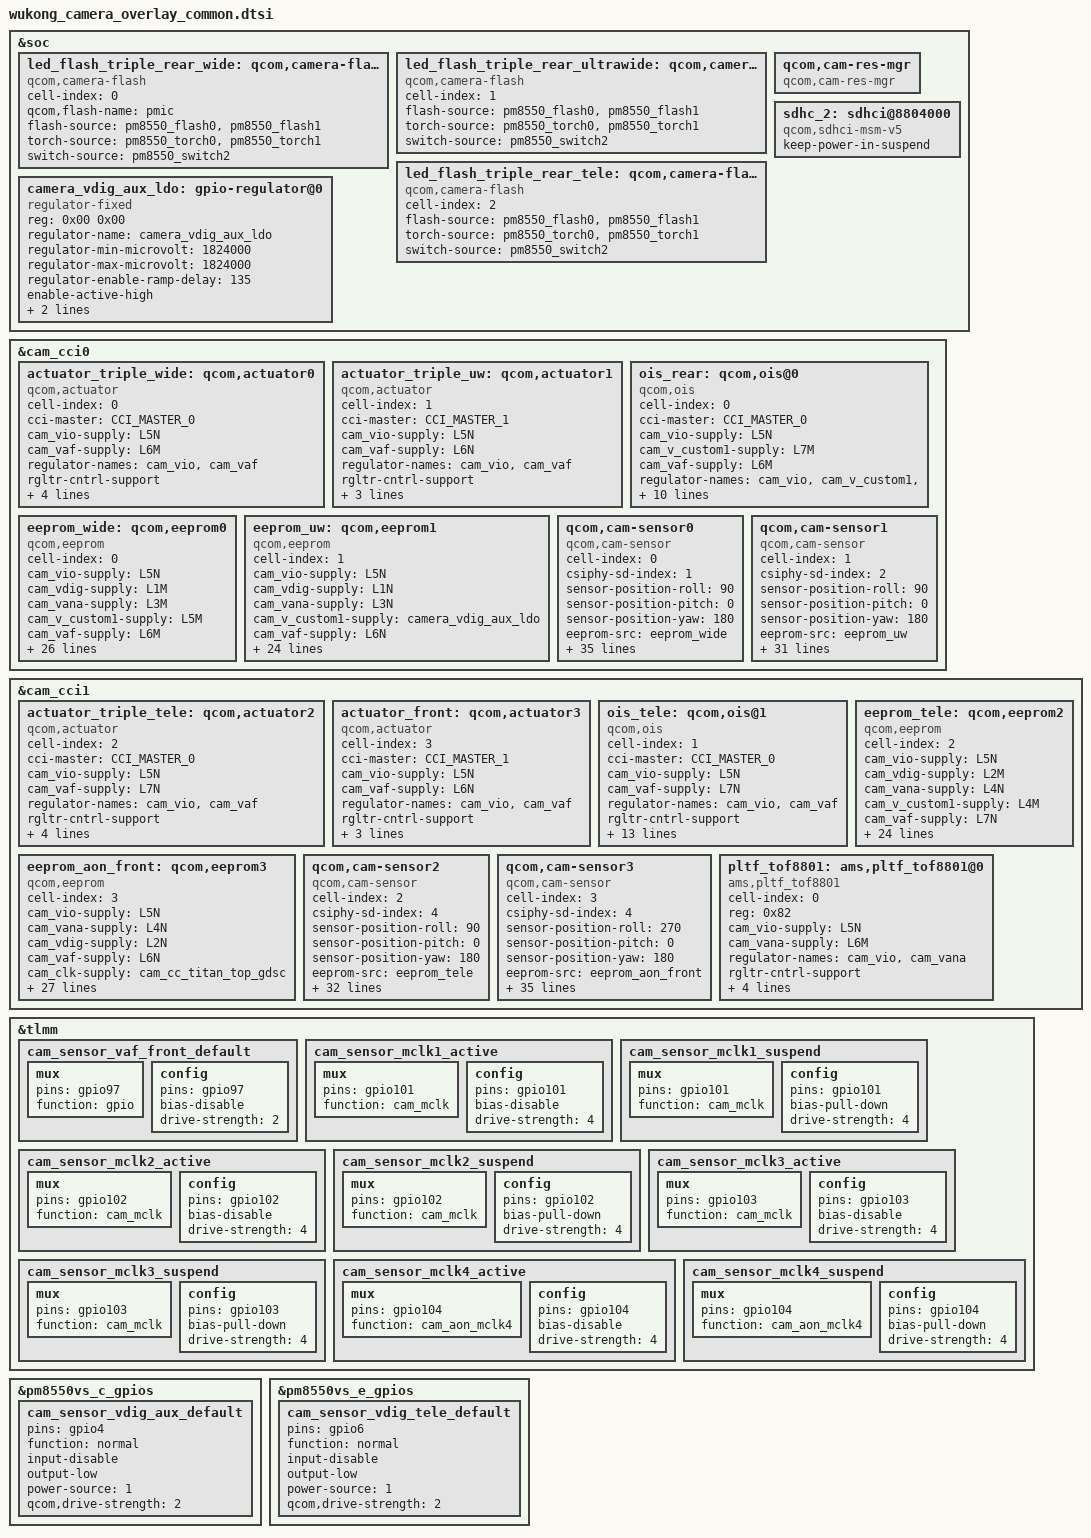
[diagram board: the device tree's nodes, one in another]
#include <dt-bindings/msm-camera.h>

&soc {
	led_flash_triple_rear_wide: qcom,camera-flash0 {
		cell-index = <0>;
		compatible = "qcom,camera-flash";
		qcom,flash-name = "pmic";
		flash-source = <&pm8550_flash0 &pm8550_flash1>;
		torch-source = <&pm8550_torch0 &pm8550_torch1>;
		switch-source = <&pm8550_switch2>;
		status = "ok";
	};

	led_flash_triple_rear_ultrawide: qcom,camera-flash1 {
		cell-index = <1>;
		compatible = "qcom,camera-flash";
		flash-source = <&pm8550_flash0 &pm8550_flash1>;
		torch-source = <&pm8550_torch0 &pm8550_torch1>;
		switch-source = <&pm8550_switch2>;
		status = "ok";
	};

	led_flash_triple_rear_tele: qcom,camera-flash2 {
		cell-index = <2>;
		compatible = "qcom,camera-flash";
		flash-source = <&pm8550_flash0 &pm8550_flash1>;
		torch-source = <&pm8550_torch0 &pm8550_torch1>;
		switch-source = <&pm8550_switch2>;
		status = "ok";
	};

	camera_vdig_aux_ldo: gpio-regulator@0 {
		compatible = "regulator-fixed";
		reg = <0x00 0x00>;
		regulator-name = "camera_vdig_aux_ldo";
		regulator-min-microvolt = <1824000>;
		regulator-max-microvolt = <1824000>;
		regulator-enable-ramp-delay = <135>;
		enable-active-high;
		gpio = <&pm8550vs_c_gpios 4 0>;
		pinctrl-names = "default";
		pinctrl-0 = <&cam_sensor_vdig_aux_default>;
		//vin-supply = <&S6G>;
	};


	qcom,cam-res-mgr {
		compatible = "qcom,cam-res-mgr";
		status = "ok";
	};

	sdhc_2: sdhci@8804000 {
		compatible = "qcom,sdhci-msm-v5";
		keep-power-in-suspend;
		status = "ok";
	};
};



&cam_cci0 {
	actuator_triple_wide: qcom,actuator0 {
		cell-index = <0>;
		compatible = "qcom,actuator";
		cci-master = <CCI_MASTER_0>;
		cam_vio-supply = <&L5N>;
		cam_vaf-supply = <&L6M>;
		regulator-names = "cam_vio", "cam_vaf";
		rgltr-cntrl-support;
		rgltr-min-voltage = <1800000 3152000>;
		rgltr-max-voltage = <1800000 3152000>;
		rgltr-load-current = <600000 300000>;
		is_af_parklens = <1>;
		status = "ok";
	};

	actuator_triple_uw: qcom,actuator1 {
		cell-index = <1>;
		compatible = "qcom,actuator";
		cci-master = <CCI_MASTER_1>;
		cam_vio-supply = <&L5N>;
		cam_vaf-supply = <&L6N>;
		regulator-names = "cam_vio", "cam_vaf";
		rgltr-cntrl-support;
		rgltr-min-voltage = <1800000 2800000>;
		rgltr-max-voltage = <1800000 2800000>;
		rgltr-load-current = <600000 300000>;
		status = "ok";
	};

	ois_rear: qcom,ois@0{
		cell-index = <0>;
		compatible = "qcom,ois";
		cci-master = <CCI_MASTER_0>;
		cam_vio-supply = <&L5N>;
		cam_v_custom1-supply = <&L7M>;
		cam_vaf-supply = <&L6M>;
		regulator-names = "cam_vio","cam_v_custom1", "cam_vaf";
		rgltr-cntrl-support;
		rgltr-min-voltage = <1800000 3152000 3152000>;
		rgltr-max-voltage = <1800000 3152000 3152000>;
		rgltr-load-current = <600000 300000 300000>;
		ois_gyro,position=<3>;
		ois_gyro,type=<3>;
		ois,type=<0>;
		ois,name="ak7323";
		ois,fw=<1>;
		status = "ok";
	};

	eeprom_wide: qcom,eeprom0 {
		cell-index = <0>;
		compatible = "qcom,eeprom";
		cam_vio-supply = <&L5N>;
		cam_vdig-supply = <&L1M>;
		cam_vana-supply = <&L3M>;
		cam_v_custom1-supply = <&L5M>;
		cam_vaf-supply = <&L6M>;
		cam_v_custom2-supply = <&L7M>;
		cam_clk-supply = <&cam_cc_titan_top_gdsc>;
		regulator-names = "cam_vio", "cam_vana", "cam_v_custom1", "cam_vdig", "cam_vaf","cam_v_custom2",
		                  "cam_clk";
		rgltr-cntrl-support;
		rgltr-min-voltage = <1800000 2904000 1800000 1152000 3152000 3152000 0>;
		rgltr-max-voltage = <1800000 2904000 1800000 1152000 3152000 3152000 0>;
		rgltr-load-current = <600000 600000 300000 1200000 300000 300000 0>;
		gpio-no-mux = <0>;
		pinctrl-names = "cam_default", "cam_suspend";
		pinctrl-0 = <&cam_sensor_mclk2_active
			&cam_sensor_active_rst1>;
		pinctrl-1 = <&cam_sensor_mclk2_suspend
			&cam_sensor_suspend_rst1>;
		gpios = <&tlmm 102 0>,
			<&tlmm 117 0>;
		gpio-reset = <1>;
		gpio-req-tbl-num = <0 1>;
		gpio-req-tbl-flags = <1 0>;
		gpio-req-tbl-label = "CAMIF_MCLK2",
					"CAM_RESET1";
		cci-master = <CCI_MASTER_0>;
		clocks = <&camcc CAM_CC_MCLK2_CLK>;
		clock-names = "cam_clk";
		clock-cntl-level = "nominal";
		clock-rates = <19200000>;
		status = "ok";
	};

	eeprom_uw: qcom,eeprom1 {
		cell-index = <1>;
		compatible = "qcom,eeprom";
		cam_vio-supply = <&L5N>;
		cam_vdig-supply = <&L1N>;
		cam_vana-supply = <&L3N>;
		cam_v_custom1-supply = <&camera_vdig_aux_ldo>;
		cam_vaf-supply = <&L6N>;
		cam_clk-supply = <&cam_cc_titan_top_gdsc>;
		regulator-names = "cam_vio", "cam_vana", "cam_v_custom1", "cam_vaf",
			"cam_vdig", "cam_clk";
		rgltr-cntrl-support;
		rgltr-min-voltage = <1800000 2800000 1824000 2800000 1152000 0>;
		rgltr-max-voltage = <1800000 2800000 1824000 2800000 1152000 0>;
		rgltr-load-current = <600000 300000 400000 300000 1200000 0>;
		gpio-no-mux = <0>;
		pinctrl-names = "cam_default", "cam_suspend";
		pinctrl-0 = <&cam_sensor_mclk1_active
				 &cam_sensor_active_rst2>;
		pinctrl-1 = <&cam_sensor_mclk1_suspend
				 &cam_sensor_suspend_rst2>;
		gpios = <&tlmm 101 0>,
			<&tlmm 118 0>;
		gpio-reset = <1>;
		gpio-req-tbl-num = <0 1>;
		gpio-req-tbl-flags = <1 0>;
		gpio-req-tbl-label = "CAMIF_MCLK1",
					"CAM_RESET2";
		cci-master = <CCI_MASTER_1>;
		clocks = <&camcc CAM_CC_MCLK1_CLK>;
		clock-names = "cam_clk";
		clock-cntl-level = "nominal";
		clock-rates = <19200000>;
		status = "ok";
	};
    //main camera
	qcom,cam-sensor0 {
		cell-index = <0>;
		compatible = "qcom,cam-sensor";
		csiphy-sd-index = <1>;
		sensor-position-roll = <90>;
		sensor-position-pitch = <0>;
		sensor-position-yaw = <180>;
		eeprom-src = <&eeprom_wide>;
		actuator-src = <&actuator_triple_wide>;
		led-flash-src = <&led_flash_triple_rear_wide>;
		ois-src = <&ois_rear>;
		cam_vio-supply = <&L5N>;
		cam_vdig-supply = <&L1M>;
		cam_vana-supply = <&L3M>;
		cam_v_custom1-supply = <&L5M>;
		cam_vaf-supply = <&L6M>;
		cam_v_custom2-supply = <&L7M>;
		cam_clk-supply = <&cam_cc_titan_top_gdsc>;
		regulator-names = "cam_vio", "cam_vana", "cam_v_custom1", "cam_vdig", "cam_vaf","cam_v_custom2",
		                  "cam_clk";
		rgltr-cntrl-support;
		rgltr-min-voltage = <1800000 2904000 1800000 1152000 3152000 3152000 0>;
		rgltr-max-voltage = <1800000 2904000 1800000 1152000 3152000 3152000 0>;
		rgltr-load-current = <600000 600000 300000 1200000 300000 300000 0>;
		gpio-no-mux = <0>;
		pinctrl-names = "cam_default", "cam_suspend";
		pinctrl-0 = <&cam_sensor_mclk2_active
			&cam_sensor_active_rst1>;
		pinctrl-1 = <&cam_sensor_mclk2_suspend
			&cam_sensor_suspend_rst1>;
		gpios = <&tlmm 102 0>,
			<&tlmm 117 0>;
		gpio-reset = <1>;
		gpio-req-tbl-num = <0 1>;
		gpio-req-tbl-flags = <1 0>;
		gpio-req-tbl-label = "CAMIF_MCLK2",
					"CAM_RESET1";
		cci-master = <CCI_MASTER_0>;
		clocks = <&camcc CAM_CC_MCLK2_CLK>;
		clock-names = "cam_clk";
		clock-cntl-level = "nominal";
		clock-rates = <19200000>;
		is-support-laser = <1>;
		status = "ok";
	};
    //wide camera
	qcom,cam-sensor1 {
		cell-index = <1>;
		compatible = "qcom,cam-sensor";
		csiphy-sd-index = <2>;
		sensor-position-roll = <90>;
		sensor-position-pitch = <0>;
		sensor-position-yaw = <180>;
		eeprom-src = <&eeprom_uw>;
		actuator-src = <&actuator_triple_uw>;
		led-flash-src = <&led_flash_triple_rear_ultrawide>;
		cam_vio-supply = <&L5N>;
		cam_vdig-supply = <&L1N>;
		cam_vana-supply = <&L3N>;
		cam_v_custom1-supply = <&camera_vdig_aux_ldo>;
		cam_vaf-supply = <&L6N>;
		cam_clk-supply = <&cam_cc_titan_top_gdsc>;
		regulator-names = "cam_vio", "cam_vana", "cam_v_custom1", "cam_vaf",
			"cam_vdig", "cam_clk";
		rgltr-cntrl-support;
		rgltr-min-voltage = <1800000 2800000 1824000 2800000 1152000 0>;
		rgltr-max-voltage = <1800000 2800000 1824000 2800000 1152000 0>;
		rgltr-load-current = <600000 300000 400000 300000 1200000 0>;
		gpio-no-mux = <0>;
		pinctrl-names = "cam_default", "cam_suspend";
		pinctrl-0 = <&cam_sensor_mclk1_active
				 &cam_sensor_active_rst2>;
		pinctrl-1 = <&cam_sensor_mclk1_suspend
				 &cam_sensor_suspend_rst2>;
		gpios = <&tlmm 101 0>,
			<&tlmm 118 0>;
		gpio-reset = <1>;
		gpio-req-tbl-num = <0 1>;
		gpio-req-tbl-flags = <1 0>;
		gpio-req-tbl-label = "CAMIF_MCLK1",
					"CAM_RESET2";
		cci-master = <CCI_MASTER_1>;
		clocks = <&camcc CAM_CC_MCLK1_CLK>;
		clock-names = "cam_clk";
		clock-cntl-level = "nominal";
		clock-rates = <19200000>;
		status = "ok";
	};

};

&cam_cci1 {
	actuator_triple_tele: qcom,actuator2{
		cell-index = <2>;
		compatible = "qcom,actuator";
		cci-master = <CCI_MASTER_0>;
		cam_vio-supply = <&L5N>;
		cam_vaf-supply = <&L7N>;
		regulator-names = "cam_vio","cam_vaf";
		rgltr-cntrl-support;
		rgltr-min-voltage = <1800000 2800000>;
		rgltr-max-voltage = <1800000 2800000>;
		rgltr-load-current = <600000 600000>;
		is_update_pid;
		status = "ok";
	};

	actuator_front: qcom,actuator3{
		cell-index = <3>;
		compatible = "qcom,actuator";
		cci-master = <CCI_MASTER_1>;
		cam_vio-supply = <&L5N>;
		cam_vaf-supply = <&L6N>;
		regulator-names = "cam_vio", "cam_vaf";
		rgltr-cntrl-support;
		rgltr-min-voltage = <1800000 2800000>;
		rgltr-max-voltage = <1800000 2800000>;
		rgltr-load-current = <600000 300000>;
		status = "ok";
	};

	ois_tele: qcom,ois@1{
		cell-index = <1>;
		compatible = "qcom,ois";
		cci-master = <CCI_MASTER_0>;
		cam_vio-supply = <&L5N>;
		cam_vaf-supply = <&L7N>;
		regulator-names = "cam_vio", "cam_vaf";
		rgltr-cntrl-support;
		rgltr-min-voltage = <1800000 2800000>;
		rgltr-max-voltage = <1800000 2800000>;
		rgltr-load-current = <600000 600000>;
		ois_gyro,position=<3>;
		ois_gyro,type=<0>;
		ois,type=<1>;
		ois,name="bu24721";
		ois_module,vendor=<1>;
		ois_actuator,vednor=<2>;
		ois,fw=<1>;
		download,fw=<1>;
		ois_eis_function = <5>;
		ois_switch_spi_mode=<1>;
		status = "ok";
	};

	eeprom_tele: qcom,eeprom2 {
		cell-index = <2>;
		compatible = "qcom,eeprom";
		cam_vio-supply = <&L5N>;
		cam_vdig-supply = <&L2M>;
		cam_vana-supply = <&L4N>;
		cam_v_custom1-supply = <&L4M>;
		cam_vaf-supply = <&L7N>;
		cam_clk-supply = <&cam_cc_titan_top_gdsc>;
		regulator-names = "cam_vio",  "cam_vdig","cam_vana", "cam_v_custom1", "cam_vaf", "cam_clk";
		rgltr-cntrl-support;
		rgltr-min-voltage = <1800000 1152000 2800000 1800000 2800000 0>;
		rgltr-max-voltage = <1800000 1152000 2904000 1800000 2800000 0>;
		rgltr-load-current = <600000 1200000 300000 600000 600000 0>;
		gpio-no-mux = <0>;
		pinctrl-names = "cam_default", "cam_suspend";
		pinctrl-0 = <&cam_sensor_mclk3_active
				 &cam_sensor_active_rst3>;
		pinctrl-1 = <&cam_sensor_mclk3_suspend
				 &cam_sensor_suspend_rst3>;
		gpios = <&tlmm 103 0>,
			<&tlmm 119 0>;
		gpio-reset = <1>;
		gpio-req-tbl-num = <0 1>;
		gpio-req-tbl-flags = <1 0>;
		gpio-req-tbl-label = "CAMIF_MCLK3",
					"CAM_RESET3";
		cci-master = <CCI_MASTER_0>;
		clocks = <&camcc CAM_CC_MCLK3_CLK>;
		clock-names = "cam_clk";
		clock-cntl-level = "nominal";
		clock-rates = <19200000>;
		status = "ok";
	};

	eeprom_aon_front: qcom,eeprom3 {
		cell-index = <3>;
		compatible = "qcom,eeprom";
		cam_vio-supply = <&L5N>;
		cam_vana-supply = <&L4N>;
		cam_vdig-supply = <&L2N>;
		cam_vaf-supply = <&L6N>;
		cam_clk-supply = <&cam_cc_titan_top_gdsc>;
		regulator-names = "cam_vio", "cam_vdig", "cam_vana", "cam_vaf", "cam_clk";
		rgltr-cntrl-support;
		rgltr-min-voltage = <1800000 848000 2904000 2800000 0>;
		rgltr-max-voltage = <1800000 848000 2904000 2800000 0>;
		rgltr-load-current = <600000 1200000 300000 300000 0>;
		gpio-no-mux = <0>;
		pinctrl-names = "cam_default", "cam_suspend";
		pinctrl-0 = <&cam_sensor_mclk4_active
				 &cam_sensor_active_rst4
				 &cam_sensor_ponv_active>;
		pinctrl-1 = <&cam_sensor_mclk4_suspend
				 &cam_sensor_suspend_rst4
				 &cam_sensor_ponv_suspend>;
		gpios = <&tlmm 104 0>,
			<&tlmm 120 0>,
			<&tlmm 206 0>;
		gpio-reset = <1>;
		gpio-standby = <2>;
		gpio-req-tbl-num = <0 1 2>;
		gpio-req-tbl-flags = <1 0 0>;
		gpio-req-tbl-label = "CAMIF_MCLK4",
					"CAM_RESET4",
					"CAM_STANDBY";
		cci-master = <CCI_MASTER_1>;
		clocks = <&camcc CAM_CC_MCLK4_CLK>;
		clock-names = "cam_clk";
		clock-cntl-level = "nominal";
		clock-rates = <19200000>;
		status = "ok";
	};

	qcom,cam-sensor2 {
		cell-index = <2>;
		compatible = "qcom,cam-sensor";
		csiphy-sd-index = <4>;
		sensor-position-roll = <90>;
		sensor-position-pitch = <0>;
		sensor-position-yaw = <180>;
		eeprom-src = <&eeprom_tele>;
		actuator-src = <&actuator_triple_tele>;
		led-flash-src = <&led_flash_triple_rear_tele>;
		ois-src = <&ois_tele>;
		cam_vio-supply = <&L5N>;
		cam_vdig-supply = <&L2M>;
		cam_vana-supply = <&L4N>;
		cam_v_custom1-supply = <&L4M>;
		cam_vaf-supply = <&L7N>;
		cam_clk-supply = <&cam_cc_titan_top_gdsc>;
		regulator-names = "cam_vio",  "cam_vdig","cam_vana", "cam_v_custom1", "cam_vaf", "cam_clk";
		rgltr-cntrl-support;
		rgltr-min-voltage = <1800000 1152000 2800000 1800000 2800000 0>;
		rgltr-max-voltage = <1800000 1152000 2904000 1800000 2800000 0>;
		rgltr-load-current = <600000 1200000 300000 600000 600000 0>;
		gpio-no-mux = <0>;
		pinctrl-names = "cam_default", "cam_suspend";
		pinctrl-0 = <&cam_sensor_mclk3_active
				 &cam_sensor_active_rst3>;
		pinctrl-1 = <&cam_sensor_mclk3_suspend
				 &cam_sensor_suspend_rst3>;
		gpios = <&tlmm 103 0>,
			<&tlmm 119 0>;
		gpio-reset = <1>;
		gpio-req-tbl-num = <0 1>;
		gpio-req-tbl-flags = <1 0>;
		gpio-req-tbl-label = "CAMIF_MCLK3",
					"CAM_RESET3";
		cci-master = <CCI_MASTER_0>;
		clocks = <&camcc CAM_CC_MCLK3_CLK>;
		clock-names = "cam_clk";
		clock-cntl-level = "nominal";
		clock-rates = <19200000>;
		status = "ok";
	};

	qcom,cam-sensor3 {
		cell-index = <3>;
		compatible = "qcom,cam-sensor","zeku,aon-sensor";
		csiphy-sd-index = <4>;
		sensor-position-roll = <270>;
		sensor-position-pitch = <0>;
		sensor-position-yaw = <180>;
		eeprom-src = <&eeprom_aon_front>;
		actuator-src = <&actuator_front>;
		cam_vio-supply = <&L5N>;
		cam_vana-supply = <&L4N>;
		cam_vdig-supply = <&L2N>;
		cam_vaf-supply = <&L6N>;
		cam_clk-supply = <&cam_cc_titan_top_gdsc>;
		regulator-names = "cam_vio", "cam_vdig", "cam_vana", "cam_vaf", "cam_clk";
		rgltr-cntrl-support;
		rgltr-min-voltage = <1800000 848000 2904000 2800000 0>;
		rgltr-max-voltage = <1800000 848000 2904000 2800000 0>;
		rgltr-load-current = <600000 1200000 300000 300000 0>;
		gpio-no-mux = <0>;
		pinctrl-names = "cam_default", "cam_suspend";
		pinctrl-0 = <&cam_sensor_mclk4_active
				 &cam_sensor_active_rst4
				 &cam_sensor_ponv_active>;
		pinctrl-1 = <&cam_sensor_mclk4_suspend
				 &cam_sensor_suspend_rst4
				 &cam_sensor_ponv_suspend>;
		gpios = <&tlmm 104 0>,
			<&tlmm 120 0>,
			<&tlmm 206 0>;
		gpio-reset = <1>;
		gpio-custom1 = <2>;
		gpio-req-tbl-num = <0 1 2>;
		gpio-req-tbl-flags = <1 0 0>;
		gpio-req-tbl-label = "CAMIF_MCLK4",
					"CAM_RESET4",
					"CAM_PONV_FRONT";
		cci-master = <CCI_MASTER_1>;
                qcom-aon-irq-gpio = <&tlmm 207 0>;
		clocks = <&camcc CAM_CC_MCLK4_CLK>;
		clock-names = "cam_clk";
		clock-cntl-level = "nominal";
		clock-rates = <19200000>;
		status = "ok";
		lock-cci-during-up;
	};

    pltf_tof8801: ams,pltf_tof8801@0 {
        cell-index = <0>;
        reg = <0x82>;
        compatible = "ams,pltf_tof8801";
        cam_vio-supply = <&L5N>;
        cam_vana-supply = <&L6M>;
        regulator-names = "cam_vio", "cam_vana";
        rgltr-cntrl-support;
        rgltr-min-voltage = <1800000 3152000>;
        rgltr-max-voltage = <1800000 3152000>;
        rgltr-load-current = <600000 700000>;
        cci-master = <CCI_MASTER_1>;
        status = "ok";
    };
};

&tlmm {
	cam_sensor_vaf_front_default: cam_sensor_vaf_front_default {
		/*  VIO LDO */
		mux {
			pins = "gpio97";
			function = "gpio";
		};

		config {
			pins = "gpio97";
			bias-disable; /* No PULL */
			drive-strength = <2>; /* 2 MA */
		};
	};

	cam_sensor_mclk1_active: cam_sensor_mclk1_active {
		/* MCLK1 */
		mux {
			pins = "gpio101";
			function = "cam_mclk";
		};

		config {
			pins = "gpio101";
			bias-disable; /* No PULL */
			drive-strength = <4>; /* 2 MA */
		};
	};

	cam_sensor_mclk1_suspend: cam_sensor_mclk1_suspend {
		/* MCLK1 */
		mux {
			pins = "gpio101";
			function = "cam_mclk";
		};

		config {
			pins = "gpio101";
			bias-pull-down; /* PULL DOWN */
			drive-strength = <4>; /* 2 MA */
		};
	};

	cam_sensor_mclk2_active: cam_sensor_mclk2_active {
		/* MCLK2 */
		mux {
			pins = "gpio102";
			function = "cam_mclk";
		};

		config {
			pins = "gpio102";
			bias-disable; /* No PULL */
			drive-strength = <4>; /* 2 MA */
		};
	};

	cam_sensor_mclk2_suspend: cam_sensor_mclk2_suspend {
		/* MCLK2 */
		mux {
			pins = "gpio102";
			function = "cam_mclk";
		};

		config {
			pins = "gpio102";
			bias-pull-down; /* PULL DOWN */
			drive-strength = <4>; /* 2 MA */
		};
	};

	cam_sensor_mclk3_active: cam_sensor_mclk3_active {
		/* MCLK3 */
		mux {
			pins = "gpio103";
			function = "cam_mclk";
		};

		config {
			pins = "gpio103";
			bias-disable; /* No PULL */
			drive-strength = <4>; /* 2 MA */
		};
	};

	cam_sensor_mclk3_suspend: cam_sensor_mclk3_suspend {
		/* MCLK3 */
		mux {
			pins = "gpio103";
			function = "cam_mclk";
		};

		config {
			pins = "gpio103";
			bias-pull-down; /* PULL DOWN */
			drive-strength = <4>; /* 2 MA */
		};
	};

	cam_sensor_mclk4_active: cam_sensor_mclk4_active {
		/* MCLK4 */
		mux {
			pins = "gpio104";
			function = "cam_aon_mclk4";
		};

		config {
			pins = "gpio104";
			bias-disable; /* No PULL */
			drive-strength = <4>; /* 2 MA */
		};
	};

	cam_sensor_mclk4_suspend: cam_sensor_mclk4_suspend {
		/* MCLK4 */
		mux {
			pins = "gpio104";
			function = "cam_aon_mclk4";
		};

		config {
			pins = "gpio104";
			bias-pull-down; /* PULL DOWN */
			drive-strength = <4>; /* 2 MA */
		};
	};
};
&pm8550vs_c_gpios {
		cam_sensor_vdig_aux_default: cam_sensor_vdig_aux_default {
			pins = "gpio4";
			function = "normal";
			input-disable;
			output-low;
			power-source = <1>; /* 1.8V */
			qcom,drive-strength = <2>;
		};
};
&pm8550vs_e_gpios {
		cam_sensor_vdig_tele_default: cam_sensor_vdig_tele_default {
			pins = "gpio6";
			function = "normal";
			input-disable;
			output-low;
			power-source = <1>; /* 1.8V */
			qcom,drive-strength = <2>;
		};
};
